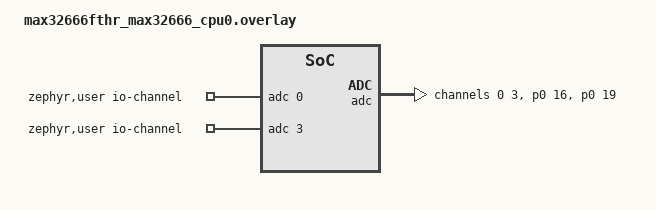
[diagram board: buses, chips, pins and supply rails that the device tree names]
/*
 * Copyright (c) 2023 Analog Devices, Inc.
 *
 * SPDX-License-Identifier: Apache-2.0
 */

/ {
	zephyr,user {
		/* adjust channel number according to pinmux in board.dts */
		io-channels = <&adc 0>, <&adc 3>;
	};
};

&adc {
	status = "okay";
	pinctrl-0 = <&ain0n_p0_16 &ain1p_p0_19>;
	pinctrl-names = "default";
	#address-cells = <1>;
	#size-cells = <0>;

	channel@0 {
		reg = <0>;
		zephyr,gain = "ADC_GAIN_1";
		zephyr,reference = "ADC_REF_INTERNAL";
		zephyr,acquisition-time = <ADC_ACQ_TIME_DEFAULT>;
		zephyr,resolution = <10>;
	};

	channel@3 {
		reg = <3>;
		zephyr,gain = "ADC_GAIN_1";
		zephyr,reference = "ADC_REF_INTERNAL";
		zephyr,acquisition-time = <ADC_ACQ_TIME_DEFAULT>;
		zephyr,resolution = <10>;
	};
};
